# STM32H753 register map
File version: 1.8
CPU: CM7 r0p1, little endian, MPU, FPU, 4 interrupt priority bits
Registers are 32-bit, read-write, reset 0x0 unless marked. A register's access mark holds for its fields unless they carry their own. Offsets are from the block's base; [hi:lo] are bit positions; {n}, {i} and the like mark numbered series; 'fields as' and 'values as' point back to an identical list.

## DMAMUX2 — DMAMUX
Base 0x58025800
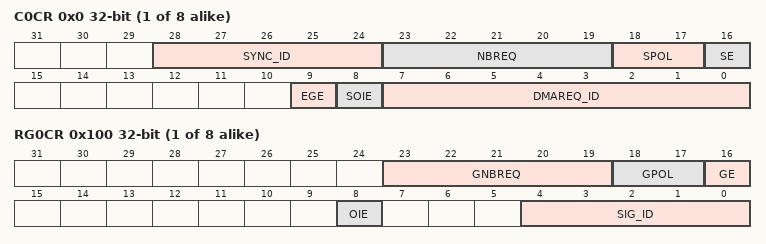
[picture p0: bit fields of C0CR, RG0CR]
{0x0+4i} C{i}CR (i=0..7) — DMAMux - DMA request line multiplexer channel x control register
  [28:24] SYNC_ID — Synchronization input selected
  [23:19] NBREQ — Number of DMA requests to forward Defines the number of DMA requests forwarded before output event is generated. In synchronous mode, it also defines the number of DMA requests to forward after a synchronization event, then stop forwarding. The actual number of DMA requests forwarded is NBREQ+1. Note: This field can only be written when both SE and EGE bits are reset.
  [18:17] SPOL — Synchronization event type selector Defines the synchronization event on the selected synchronization input:
  [16] SE — Synchronous operating mode enable/disable
  [9] EGE — Event generation enable/disable
  [8] SOIE — Interrupt enable at synchronization event overrun
  [7:0] DMAREQ_ID — Input DMA request line selected
0x80 CSR ro — DMAMUX request line multiplexer interrupt channel status register
  [15:0] SOF — Synchronization overrun event flag
0x84 CFR wo — DMAMUX request line multiplexer interrupt clear flag register
  [15:0] CSOF — Clear synchronization overrun event flag
{0x100+4i} RG{i}CR (i=0..7) — DMAMux - DMA request generator channel x control register
  [23:19] GNBREQ — Number of DMA requests to generate Defines the number of DMA requests generated after a trigger event, then stop generating. The actual number of generated DMA requests is GNBREQ+1. Note: This field can only be written when GE bit is reset.
  [18:17] GPOL — DMA request generator trigger event type selection Defines the trigger event on the selected DMA request trigger input
  [16] GE — DMA request generator channel enable/disable
  [8] OIE — Interrupt enable at trigger event overrun
  [4:0] SIG_ID — DMA request trigger input selected
0x140 RGSR ro — DMAMux - DMA request generator status register
  [7:0] OF — Trigger event overrun flag The flag is set when a trigger event occurs on DMA request generator channel x, while the DMA request generator counter value is lower than GNBREQ. The flag is cleared by writing 1 to the corresponding COFx bit in DMAMUX_RGCFR register.
0x144 RGCFR wo — DMAMux - DMA request generator clear flag register
  [7:0] COF — Clear trigger event overrun flag Upon setting, this bit clears the corresponding overrun flag OFx in the DMAMUX_RGCSR register.

## HSEM
Base 0x58026400
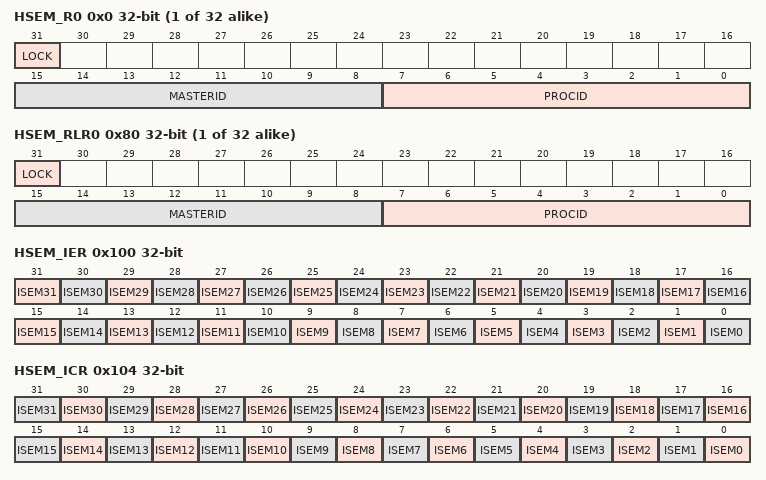
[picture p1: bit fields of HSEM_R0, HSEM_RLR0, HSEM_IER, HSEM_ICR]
{0x0+4i} HSEM_R{i} (i=0..31) — HSEM register HSEM_R0 HSEM_R31
  [31] LOCK — Lock indication
  [15:8] MASTERID — Semaphore MasterID
  [7:0] PROCID — Semaphore ProcessID
{0x80+4i} HSEM_RLR{i} ro (i=0..31) — HSEM Read lock register
  fields as HSEM_R0
0x100 HSEM_IER — HSEM Interrupt enable register
  [31] ISEM31 — Interrupt(N) semaphore n enable bit.
  [n] ISEM{n} (n=0..30) — Interrupt semaphore n enable bit
0x104 HSEM_ICR ro — HSEM Interrupt clear register
  [n] ISEM{n} (n=0..31) — Interrupt(N) semaphore n clear bit
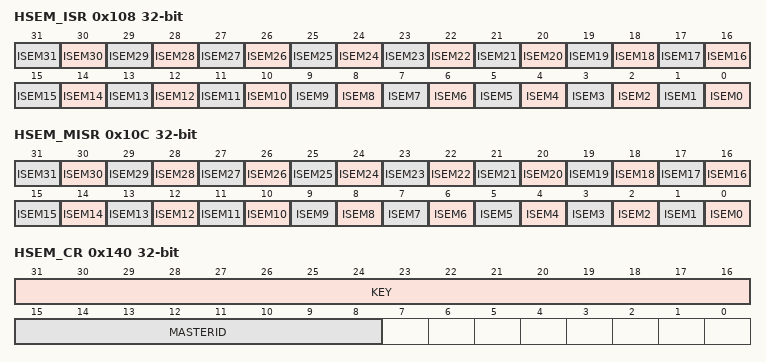
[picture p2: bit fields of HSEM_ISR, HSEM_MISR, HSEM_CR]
0x108 HSEM_ISR ro — HSEM Interrupt status register
  [n] ISEM{n} (n=0..31) — Interrupt(N) semaphore n status bit before enable (mask)
0x10C HSEM_MISR ro — HSEM Masked interrupt status register
  [n] ISEM{n} (n=0..31) — masked interrupt(N) semaphore n status bit after enable (mask)
0x140 HSEM_CR — HSEM Clear register
  [31:16] KEY — Semaphore clear Key
  [15:8] MASTERID — MasterID of semaphores to be cleared
0x144 HSEM_KEYR — HSEM Interrupt clear register
  [31:16] KEY — Semaphore Clear Key

## RNG
Base 0x48021800
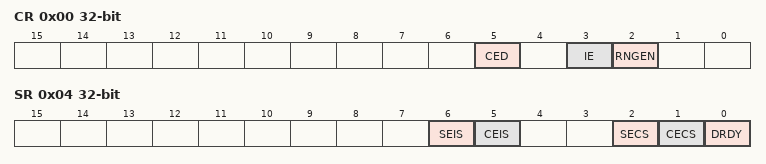
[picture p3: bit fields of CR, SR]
0x00 CR — RNG control register
  [5] CED — Clock error detection Note: The clock error detection can be used only when ck_rc48 or ck_pll1_q (ck_pll1_q = 48MHz) source is selected otherwise, CED bit must be equal to 1. The clock error detection cannot be enabled nor disabled on the fly when RNG peripheral is enabled, to enable or disable CED the RNG must be disabled.
  [3] IE — Interrupt enable
  [2] RNGEN — Random number generator enable
0x04 SR access per field — RNG status register
  [6] SEIS rw — Seed error interrupt status This bit is set at the same time as SECS. It is cleared by writing it to 0. ** More than 64 consecutive bits at the same value (0 or 1) ** More than 32 consecutive alternances of 0 and 1 (0101010101...01) An interrupt is pending if IE = 1 in the RNG_CR register.
  [5] CEIS rw — Clock error interrupt status This bit is set at the same time as CECS. It is cleared by writing it to 0. An interrupt is pending if IE = 1 in the RNG_CR register. Note: This bit is meaningless if CED (Clock error detection) bit in RNG_CR is equal to 1.
  [2] SECS ro — Seed error current status ** More than 64 consecutive bits at the same value (0 or 1) ** More than 32 consecutive alternances of 0 and 1 (0101010101...01)
  [1] CECS ro — Clock error current status Note: This bit is meaningless if CED (Clock error detection) bit in RNG_CR is equal to 1.
  [0] DRDY ro — Data ready Note: If IE=1 in RNG_CR, an interrupt is generated when DRDY=1. It can rise when the peripheral is disabled. When the output buffer becomes empty (after reading RNG_DR), this bit returns to 0 until a new random value is generated.
0x08 DR ro — The RNG_DR register is a read-only register that delivers a 32-bit random value when read. The content of this register is valid when DRDY= 1, even if RNGEN=0.
  [31:0] RNDATA — Random data 32-bit random data which are valid when DRDY=1.

## Notices in the file
Copyright (c) 2023 STMicroelectronics.
SPDX-License-Identifier: Apache-2.0
Licensed under the Apache License, Version 2.0 (the "License");
you may not use this file except in compliance with the License.
You may obtain a copy of the License at
http://www.apache.org/licenses/LICENSE-2.0
Unless required by applicable law or agreed to in writing, software
distributed under the License is distributed on an "AS IS" BASIS,
WITHOUT WARRANTIES OR CONDITIONS OF ANY KIND, either express or implied.
See the License for the specific language governing permissions and
limitations under the License.
